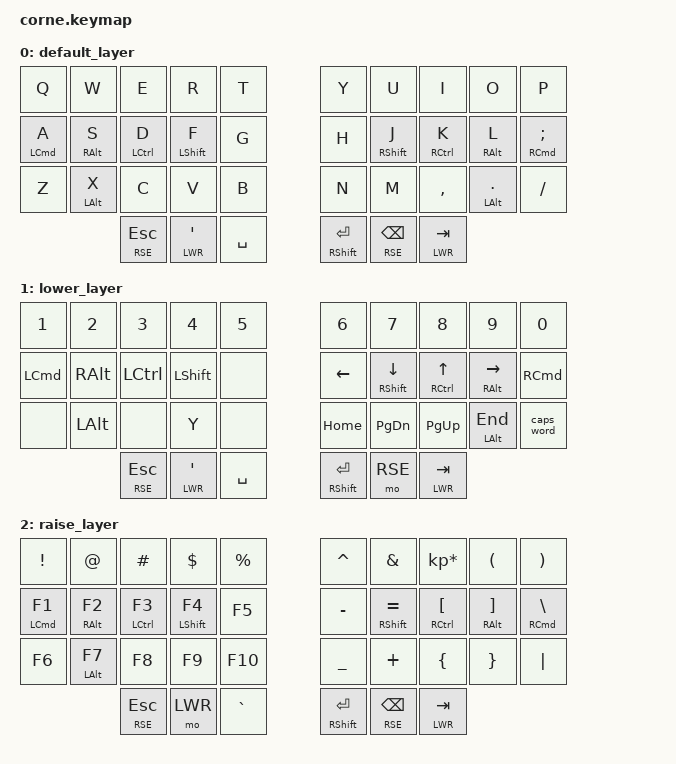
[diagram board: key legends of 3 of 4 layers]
/*
 * Copyright (c) 2020 The ZMK Contributors
 *
 * SPDX-License-Identifier: MIT
 */

/*
 * This is a keymap for Samoklava, a Corne-compatible wireless keyboard. You can use this keymap with a Corne as well.
 * To compile, run these commands:
 *
 *   west build -d build/left -b nice_nano_v2 -- -DSHIELD=corne_left -DZMK_CONFIG='../../samoklava-zmk-config/config'
 *   west build -d build/right -b nice_nano_v2 -- -DSHIELD=corne_right -DZMK_CONFIG='../../samoklava-zmk-config/config'
 *   cp build/left/zephyr/zmk.uf2 ~/Desktop/left.uf2
 *   cp build/right/zephyr/zmk.uf2 ~/Desktop/right.uf2
 */

#include <behaviors.dtsi>
#include <dt-bindings/zmk/keys.h>
#include <dt-bindings/zmk/bt.h>
#include <layouts/foostan/corne/5column.dtsi>


#define DEFAULT 0
#define LOWER   1
#define RAISE   2
#define ADJUST  3
#define LWR LOWER
#define RSE RAISE
#define ADJ ADJUST

&mt {
    quick-tap-ms = <180>;
    tapping-term-ms = <250>;
};

&lt {
    quick_tap_ms = <200>;
    tapping-term-ms = <180>;
};

&foostan_corne_5col_layout {
    transform = <&five_column_transform>;
    kscan = <&kscan0>;
    display-name = "5 Column";
};

/ {
    chosen {
        zmk,matrix_transform = &five_column_transform;
        zmk,physical_layout = &foostan_corne_5col_layout;
    };
};
/ {
        behaviors {
            //                 Key positions
            //       0  1  2  3  4    5  6  7  8  9
            //      10 11 12 13 14   15 16 17 18 19
            //      20 21 22 23 24   25 26 27 28 29
            //            30 31 32   33 34 35

            hml: homerow_mods_left {
                compatible = "zmk,behavior-hold-tap";
                label = "HOMEROW_MODS_LEFT";
                #binding-cells = <2>;
                flavor = "tap-preferred";
                tapping-term-ms = <200>;
                quick-tap-ms = <200>;
                require-prior-idle-ms = <120>;
                bindings = <&kp>, <&kp>;
                hold-trigger-key-positions = <
                                      5  6  7  8  9
                    10 11 12 13      15 16 17 18 19
                       21            25 26 27 28 29
                          30 31 32   33 34 35
                    >;    // <---[[right-hand keys + all homerow mods + all thumbs]]
            };

            hsl: homerow_shift_left {
                compatible = "zmk,behavior-hold-tap";
                label = "HOMEROW_SHIFT_LEFT";
                #binding-cells = <2>;
                flavor = "tap-preferred";
                tapping-term-ms = <200>;
                quick-tap-ms = <200>;
                require-prior-idle-ms = <50>;
                bindings = <&kp>, <&kp>;
                hold-trigger-key-positions = <
                                      5  6  7  8  9
                    10 11 12 13      15 16 17 18 19
                       21            25 26 27 28 29
                          30 31 32   33 34 35
                    >;    // <---[[right-hand keys + all homerow mods + all thumbs]]
            };

            hmr: homerow_mods_right {
                compatible = "zmk,behavior-hold-tap";
                label = "HOMEROW_MODS_RIGHT";
                #binding-cells = <2>;
                flavor = "tap-preferred";
                tapping-term-ms = <200>;
                quick-tap-ms = <200>;
                require-prior-idle-ms = <120>;
                bindings = <&kp>, <&kp>;
                hold-trigger-key-positions = <
                     0  1  2  3  4                 
                    10 11 12 13 14      16 17 18 19
                    20 21 22 23 24            28   
                          30 31 32   33 34 35
                    >;    // <---[[left-hand keys + all homerow mods + all thumbs]]
            };

            hsr: homerow_shift_right {
                compatible = "zmk,behavior-hold-tap";
                label = "HOMEROW_SHIFT_RIGHT";
                #binding-cells = <2>;
                flavor = "tap-preferred";
                tapping-term-ms = <200>;
                quick-tap-ms = <200>;
                require-prior-idle-ms = <50>;
                bindings = <&kp>, <&kp>;
                hold-trigger-key-positions = <
                     0  1  2  3  4                 
                    10 11 12 13 14      16 17 18 19
                    20 21 22 23 24            28   
                          30 31 32   33 34 35
                    >;    // <---[[left-hand keys + all homerow mods + all thumbs]]
            };
        };

        combos {
           compatible = "zmk,combos";
           combo_lpar {
              timeout-ms = <50>;
              key-positions = <20 21>;
              bindings = <&kp LPAR>;
           };

           combo_rpar {
              timeout-ms = <50>;
              key-positions = <28 29>;
              bindings = <&kp RPAR>;
           };
        };

        conditional_layers {
            compatible = "zmk,conditional-layers";
            tri_layer {
                if-layers = <LOWER RAISE>;
                then-layer = <ADJUST>;
            };
        };

        keymap {
                compatible = "zmk,keymap";

                default_layer {
                        bindings = <
   &kp Q        &kp W         &kp E        &kp R         &kp T             &kp Y         &kp U            &kp I           &kp O            &kp P
   &hml LCMD A  &hml RALT S   &hml LCTRL D &hsl LSHFT F  &kp G             &kp H         &hsr RSHFT J     &hmr RCTRL K    &hmr RALT L      &hmr RCMD SEMI
   &kp Z        &hml LALT X   &kp C        &kp V         &kp B             &kp N         &kp M            &kp COMMA       &hmr LALT DOT    &kp FSLH
                              &lt RSE ESC  &lt LWR QUOT  &kp SPACE         &mt RSHFT RET &lt RSE BSPC     &lt LWR TAB
                        >;
                };
                lower_layer {
                        bindings = <
   &kp N1       &kp N2       &kp N3        &kp N4        &kp N5            &kp N6        &kp N7           &kp N8           &kp N9          &kp N0
   &kp LCMD     &kp RALT     &kp LCTRL     &kp LSHFT     &none             &kp LEFT      &hsr RSHFT DOWN  &hmr RCTRL UP    &hmr RALT RIGHT &kp RCMD
   &none        &kp LALT     &none         &kp Y         &none             &kp HOME      &kp PG_DN        &kp PG_UP        &hmr LALT END   &caps_word
                             &lt RSE ESC   &lt LWR QUOT  &kp SPACE         &mt RSHFT RET &mo RSE          &lt LWR TAB
                        >;
                };
                raise_layer {
                        bindings = <
   &kp EXCL     &kp AT       &kp HASH      &kp DLLR      &kp PRCNT         &kp CARET     &kp AMPS         &kp KP_MULTIPLY  &kp LPAR        &kp RPAR
   &hml LCMD F1 &hml RALT F2 &hml LCTRL F3 &hsl LSHFT F4 &kp F5            &kp MINUS     &hsr RSHFT EQUAL &hmr RCTRL LBKT  &hmr RALT RBKT  &hmr RCMD BSLH
   &kp F6       &hml LALT F7 &kp F8        &kp F9        &kp F10           &kp UNDER     &kp PLUS         &kp LBRC         &kp RBRC        &kp PIPE
                             &lt RSE ESC   &mo LWR       &kp GRAVE         &mt RSHFT RET &lt RSE BSPC     &lt LWR TAB
                        >;
                };
                adjust_layer {
                        bindings = <
   // for some weird reason the 5x3 transform doesn't quite work for the adjust layer, it needs an extra offset
   &none        &bt BT_CLR   &none        &none         &none         &bt BT_DISC       &none         &kp K_MUTE       &none            &none           &bootloader
                &bt BT_SEL 0 &bt BT_SEL 1 &bt BT_SEL 2  &bt BT_SEL 3  &bt BT_SEL 4      &kp C_BRI_UP  &kp C_VOL_UP     &none            &none           &none
                &sys_reset   &none        &none         &none         &none             &kp C_BRI_DN  &kp C_VOL_DN     &none            &none           &sys_reset
                                          &none         &none         &none             &none         &none            &none
                        >;
                };
        };
}; 
